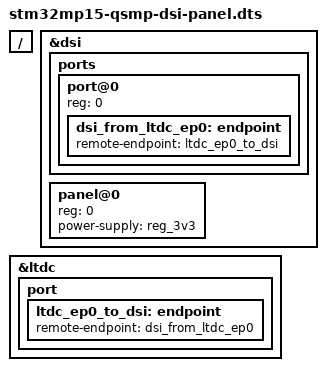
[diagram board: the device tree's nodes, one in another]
// SPDX-License-Identifier: (GPL-2.0 OR BSD-3-Clause)
/*
 * Copyright (C) 2020 Lothar Waßmann <LW@KARO-electronics.de>
 *
 */

/dts-v1/;
/plugin/;

/ {
	#address-cells = <1>;
	#size-cells = <0>;

	fragment@0 {
		reg = <0>;
		target = <&dsi>;

		__overlay__ {
			#address-cells = <1>;
			#size-cells = <0>;

			ports {
				#address-cells = <1>;
				#size-cells = <0>;

				port@0 {
					reg = <0>;

					dsi_from_ltdc_ep0: endpoint {
						remote-endpoint = <&ltdc_ep0_to_dsi>;
					};
				};
			};

			panel@0 {
				reg = <0>;
				power-supply = <&reg_3v3>;
				status = "okay";
			};
		};
	};

	fragment@1 {
		reg = <1>;
		target = <&ltdc>;

		__overlay__ {
			status = "okay";

			port {
				ltdc_ep0_to_dsi: endpoint {
					remote-endpoint = <&dsi_from_ltdc_ep0>;
				};
			};
		};
	};
};
